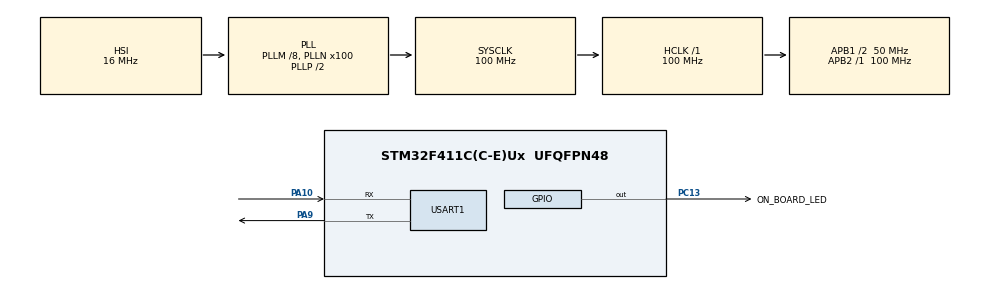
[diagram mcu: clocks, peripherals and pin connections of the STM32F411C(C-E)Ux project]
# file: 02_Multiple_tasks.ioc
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FREERTOS.Tasks01=ledblink,8,128,onboard_led_blink,Default,NULL,Dynamic,NULL,NULL;transmit_msg,9,128,UART_transmit_msg,Default,NULL,Dynamic,NULL,NULL;transmit_error,16,128,UART_transmit_errorcode,Default,NULL,Dynamic,NULL,NULL
Mcu.Family=STM32F4
Mcu.Name=STM32F411C(C-E)Ux
Mcu.Package=UFQFPN48
NVIC.PriorityGroup=NVIC_PRIORITYGROUP_4
NVIC.TIM5_IRQn=true\:15\:0\:false\:false\:true\:false\:false\:true\:true
NVIC.TimeBase=TIM5_IRQn
NVIC.TimeBaseIP=TIM5
NVIC.USART1_IRQn=true\:5\:0\:false\:false\:true\:true\:true\:true\:true
PA10.Mode=Asynchronous
PA10.Signal=USART1_RX
PA13.Mode=Serial_Wire
PA13.Signal=SYS_JTMS-SWDIO
PA14.Mode=Serial_Wire
PA14.Signal=SYS_JTCK-SWCLK
PA9.Mode=Asynchronous
PA9.Signal=USART1_TX
PC13-ANTI_TAMP.GPIO_Label=ON_BOARD_LED
PC13-ANTI_TAMP.Signal=GPIO_Output
PC14-OSC32_IN.Mode=LSE-External-Oscillator
PC14-OSC32_IN.Signal=RCC_OSC32_IN
PC15-OSC32_OUT.Mode=LSE-External-Oscillator
PC15-OSC32_OUT.Signal=RCC_OSC32_OUT
PH0\ -\ OSC_IN.Mode=HSE-External-Oscillator
PH0\ -\ OSC_IN.Signal=RCC_OSC_IN
PH1\ -\ OSC_OUT.Mode=HSE-External-Oscillator
PH1\ -\ OSC_OUT.Signal=RCC_OSC_OUT
ProjectManager.HeapSize=0x200
ProjectManager.StackSize=0x400
ProjectManager.TargetToolchain=STM32CubeIDE
RCC.48MHZClocksFreq_Value=50000000
RCC.AHBFreq_Value=100000000
RCC.APB1CLKDivider=RCC_HCLK_DIV2
RCC.APB1Freq_Value=50000000
RCC.APB1TimFreq_Value=100000000
RCC.APB2Freq_Value=100000000
RCC.APB2TimFreq_Value=100000000
RCC.CortexFreq_Value=100000000
RCC.HCLKFreq_Value=100000000
RCC.HSE_VALUE=25000000
RCC.HSI_VALUE=16000000
RCC.PLLM=8
RCC.PLLN=100
RCC.SYSCLKFreq_VALUE=100000000
RCC.SYSCLKSource=RCC_SYSCLKSOURCE_PLLCLK
RCC.VCOOutputFreq_Value=200000000
USART1.VirtualMode=VM_ASYNC
VP_FREERTOS_VS_CMSIS_V2.Mode=CMSIS_V2
VP_SYS_VS_tim5.Mode=TIM5
board=custom

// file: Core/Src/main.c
/* USER CODE BEGIN Header */
/**
  ******************************************************************************
  * @file           : main.c
  * @brief          : Main program body
  ******************************************************************************
  * @attention
  *
  * Copyright (c) 2025 STMicroelectronics.
  * All rights reserved.
  *
  * This software is licensed under terms that can be found in the LICENSE file
  * in the root directory of this software component.
  * If no LICENSE file comes with this software, it is provided AS-IS.
  *
  ******************************************************************************
  */
/* USER CODE END Header */
#include "main.h"
#include "cmsis_os.h"

/* USER CODE BEGIN Includes */
#include "stdio.h"
/* USER CODE END Includes */

UART_HandleTypeDef huart1;

/* Definitions for ledblink */
osThreadId_t ledblinkHandle;
const osThreadAttr_t ledblink_attributes = {
  .name = "ledblink",
  .stack_size = 128 * 4,
  .priority = (osPriority_t) osPriorityLow,
};
/* Definitions for transmit_msg */
osThreadId_t transmit_msgHandle;
const osThreadAttr_t transmit_msg_attributes = {
  .name = "transmit_msg",
  .stack_size = 128 * 4,
  .priority = (osPriority_t) osPriorityLow1,
};
/* Definitions for transmit_error */
osThreadId_t transmit_errorHandle;
const osThreadAttr_t transmit_error_attributes = {
  .name = "transmit_error",
  .stack_size = 128 * 4,
  .priority = (osPriority_t) osPriorityBelowNormal,
};
/* USER CODE BEGIN PV */
uint8_t Transmit_msg[50];
uint8_t Transmit_errorcode[50];
uint8_t Transmit_length[2];
/* USER CODE END PV */

void SystemClock_Config(void);
static void MX_GPIO_Init(void);
static void MX_USART1_UART_Init(void);
void onboard_led_blink(void *argument);
void UART_transmit_msg(void *argument);
void UART_transmit_errorcode(void *argument);

int main(void)
{

  /* MCU Configuration--------------------------------------------------------*/

  /* Reset of all peripherals, Initializes the Flash interface and the Systick. */
  HAL_Init();

  /* Configure the system clock */
  SystemClock_Config();

  /* Initialize all configured peripherals */
  MX_GPIO_Init();
  MX_USART1_UART_Init();
  /* USER CODE BEGIN 2 */
  osThreadNew(onboard_led_blink, NULL, &ledblink_attributes);
  osThreadNew(UART_transmit_msg, NULL, &transmit_msg_attributes);
  osThreadNew(UART_transmit_errorcode, NULL, &transmit_error_attributes);

  /* USER CODE END 2 */

  /* Init scheduler */
  osKernelInitialize();
/* USER CODE BEGIN Header */
/**
  ******************************************************************************
  * @file           : main.c
  * @brief          : Main program body
  ******************************************************************************
  * @attention
  *
  * Copyright (c) 2025 STMicroelectronics.
  * All rights reserved.
  *
  * This software is licensed under terms that can be found in the LICENSE file
  * in the root directory of this software component.
  * If no LICENSE file comes with this software, it is provided AS-IS.
  *
  ******************************************************************************
  */
/* USER CODE END Header */

  /* Start scheduler */
  osKernelStart();

  /* We should never get here as control is now taken by the scheduler */
  /* Infinite loop */
  while (1)
  {

  }
}

void SystemClock_Config(void)
{
  RCC_OscInitTypeDef RCC_OscInitStruct = {0};
  RCC_ClkInitTypeDef RCC_ClkInitStruct = {0};

  /** Configure the main internal regulator output voltage
  */
  __HAL_RCC_PWR_CLK_ENABLE();
  __HAL_PWR_VOLTAGESCALING_CONFIG(PWR_REGULATOR_VOLTAGE_SCALE1);

  /** Initializes the RCC Oscillators according to the specified parameters
  * in the RCC_OscInitTypeDef structure.
  */
  RCC_OscInitStruct.OscillatorType = RCC_OSCILLATORTYPE_HSI;
  RCC_OscInitStruct.HSIState = RCC_HSI_ON;
  RCC_OscInitStruct.HSICalibrationValue = RCC_HSICALIBRATION_DEFAULT;
  RCC_OscInitStruct.PLL.PLLState = RCC_PLL_ON;
  RCC_OscInitStruct.PLL.PLLSource = RCC_PLLSOURCE_HSI;
  RCC_OscInitStruct.PLL.PLLM = 8;
  RCC_OscInitStruct.PLL.PLLN = 100;
  RCC_OscInitStruct.PLL.PLLP = RCC_PLLP_DIV2;
  RCC_OscInitStruct.PLL.PLLQ = 4;
  if (HAL_RCC_OscConfig(&RCC_OscInitStruct) != HAL_OK)
  {
    Error_Handler();
  }

  /** Initializes the CPU, AHB and APB buses clocks
  */
  RCC_ClkInitStruct.ClockType = RCC_CLOCKTYPE_HCLK|RCC_CLOCKTYPE_SYSCLK
                              |RCC_CLOCKTYPE_PCLK1|RCC_CLOCKTYPE_PCLK2;
  RCC_ClkInitStruct.SYSCLKSource = RCC_SYSCLKSOURCE_PLLCLK;
  RCC_ClkInitStruct.AHBCLKDivider = RCC_SYSCLK_DIV1;
  RCC_ClkInitStruct.APB1CLKDivider = RCC_HCLK_DIV2;
  RCC_ClkInitStruct.APB2CLKDivider = RCC_HCLK_DIV1;

  if (HAL_RCC_ClockConfig(&RCC_ClkInitStruct, FLASH_LATENCY_3) != HAL_OK)
  {
    Error_Handler();
  }
}

static void MX_USART1_UART_Init(void)
{

  huart1.Instance = USART1;
  huart1.Init.BaudRate = 115200;
  huart1.Init.WordLength = UART_WORDLENGTH_8B;
  huart1.Init.StopBits = UART_STOPBITS_1;
  huart1.Init.Parity = UART_PARITY_NONE;
  huart1.Init.Mode = UART_MODE_TX_RX;
  huart1.Init.HwFlowCtl = UART_HWCONTROL_NONE;
  huart1.Init.OverSampling = UART_OVERSAMPLING_16;
  if (HAL_UART_Init(&huart1) != HAL_OK)
  {
    Error_Handler();
  }

}

static void MX_GPIO_Init(void)
{
  GPIO_InitTypeDef GPIO_InitStruct = {0};

  /* GPIO Ports Clock Enable */
  __HAL_RCC_GPIOC_CLK_ENABLE();
  __HAL_RCC_GPIOH_CLK_ENABLE();
  __HAL_RCC_GPIOA_CLK_ENABLE();

  /*Configure GPIO pin Output Level */
  HAL_GPIO_WritePin(ON_BOARD_LED_GPIO_Port, ON_BOARD_LED_Pin, GPIO_PIN_RESET);

  /*Configure GPIO pin : ON_BOARD_LED_Pin */
  GPIO_InitStruct.Pin = ON_BOARD_LED_Pin;
  GPIO_InitStruct.Mode = GPIO_MODE_OUTPUT_PP;
  GPIO_InitStruct.Pull = GPIO_NOPULL;
  GPIO_InitStruct.Speed = GPIO_SPEED_FREQ_LOW;
  HAL_GPIO_Init(ON_BOARD_LED_GPIO_Port, &GPIO_InitStruct);

}

void onboard_led_blink(void *argument)
{
  /* USER CODE BEGIN 5 */
  /* Infinite loop */
  for(;;)
  {
	  HAL_GPIO_TogglePin(ON_BOARD_LED_GPIO_Port, ON_BOARD_LED_Pin);
	  osDelay(3000);
  }
  /* USER CODE END 5 */
}

void UART_transmit_msg(void *argument)
{
  /* USER CODE BEGIN UART_transmit_msg */
  /* Infinite loop */
  for(;;)
  {
	  Transmit_length[0] = snprintf((char*)Transmit_msg, sizeof(Transmit_msg), "Hello from transmit msg task\r\n");
	  HAL_UART_Transmit_IT(&huart1, (const uint8_t *)Transmit_msg, Transmit_length[0]);
	  osDelay(1000);
  }
  /* USER CODE END UART_transmit_msg */
}

void UART_transmit_errorcode(void *argument)
{
  /* USER CODE BEGIN UART_transmit_errorcode */
  /* Infinite loop */
  for(;;)
  {
	  Transmit_length[1] = snprintf((char*)Transmit_errorcode, sizeof(Transmit_msg), "Hello from transmit error task\r\n");
	  HAL_UART_Transmit_IT(&huart1, (const uint8_t *)Transmit_errorcode, Transmit_length[1]);
	  osDelay(10000);
  }
  /* USER CODE END UART_transmit_errorcode */
}

void HAL_TIM_PeriodElapsedCallback(TIM_HandleTypeDef *htim)
{
  if (htim->Instance == TIM5) {
    HAL_IncTick();
  }
}

void Error_Handler(void)
{
  __disable_irq();
  while (1)
  {
  }
}
